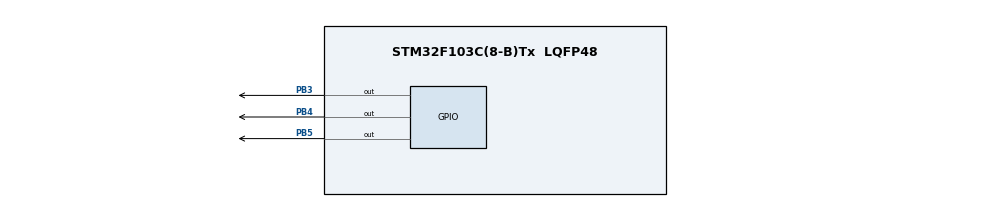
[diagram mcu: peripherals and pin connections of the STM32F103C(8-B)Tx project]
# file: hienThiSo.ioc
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Mcu.Family=STM32F1
Mcu.Name=STM32F103C(8-B)Tx
Mcu.Package=LQFP48
NVIC.PriorityGroup=NVIC_PRIORITYGROUP_4
PA13.Mode=Serial_Wire
PA13.Signal=SYS_JTMS-SWDIO
PA14.Mode=Serial_Wire
PA14.Signal=SYS_JTCK-SWCLK
PB3.Signal=GPIO_Output
PB4.Signal=GPIO_Output
PB5.Signal=GPIO_Output
ProjectManager.HeapSize=0x200
ProjectManager.StackSize=0x400
ProjectManager.TargetToolchain=MDK-ARM V5.32
RCC.APB1Freq_Value=8000000
RCC.APB2Freq_Value=8000000
board=custom

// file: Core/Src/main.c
/* USER CODE BEGIN Header */
/**
  ******************************************************************************
  * @file           : main.c
  * @brief          : Main program body
  ******************************************************************************
  * @attention
  *
  * Copyright (c) 2023 STMicroelectronics.
  * All rights reserved.
  *
  * This software is licensed under terms that can be found in the LICENSE file
  * in the root directory of this software component.
  * If no LICENSE file comes with this software, it is provided AS-IS.
  *
  ******************************************************************************
  */
/* USER CODE END Header */
#include "main.h"
#include "stdio.h"
#include <math.h>

/* USER CODE BEGIN PV */
int m[10]={0xc0,0xf9,0xa4,0xb0,0x99,0x92,0x82,0xf8,0x80,0x90};
int DATA1;
int SCK1;
int SCL1;
const uint8_t LEDTABLE[]={0B00000010,0B10011110,0B00100100,
												0B00001100,0B10011000,0B01001000,
												0B01000000,0B00011110,0B00000000,
												0B00001000};
/* USER CODE END PV */

void SystemClock_Config(void);
static void MX_GPIO_Init(void);

/* USER CODE BEGIN 0 */

	void HIEN_THI( uint8_t n)
	{
		for(int i = 0; i<8; i++){
			HAL_GPIO_WritePin(GPIOB, GPIO_PIN_5,(LEDTABLE[n]>>i)&1);
			HAL_GPIO_WritePin(GPIOB, GPIO_PIN_3, GPIO_PIN_SET);
			HAL_GPIO_WritePin(GPIOB, GPIO_PIN_3, GPIO_PIN_RESET);
		}
	}
	void HienChuoi(char x){
		int led[8];

		for (int i=0; i<8; i++){
				led[i] = fmod(x,(pow(10,i)));

					led[i] = atoi(x) ;

				HIEN_THI(led[i]);
		}
	}
/* USER CODE END 0 */

int main(void)
{

  /* MCU Configuration--------------------------------------------------------*/

  /* Reset of all peripherals, Initializes the Flash interface and the Systick. */
  HAL_Init();

  /* Configure the system clock */
  SystemClock_Config();

  /* Initialize all configured peripherals */
  MX_GPIO_Init();
  /* USER CODE BEGIN 2 */
	HAL_GPIO_WritePin(GPIOB, GPIO_PIN_3, GPIO_PIN_RESET);
	HAL_GPIO_WritePin(GPIOB, GPIO_PIN_4, GPIO_PIN_RESET);
	HAL_GPIO_WritePin(GPIOB, GPIO_PIN_5, GPIO_PIN_RESET);

	HienChuoi(3333333);
	/*
	HIEN_THI(4);
	HIEN_THI(6);
	HIEN_THI(4);
	HIEN_THI(1);
	HIEN_THI(0);
	HIEN_THI(2);
	*/

  HAL_GPIO_WritePin(GPIOB, GPIO_PIN_4, GPIO_PIN_SET); // SELECT

	HAL_Delay(1);

	HAL_GPIO_WritePin(GPIOB, GPIO_PIN_4, GPIO_PIN_RESET); // SELECT

	HAL_Delay(1);

		//HIEN_THI(mot);
		//HIEN_THI(hai);

  /* USER CODE END 2 */

  /* Infinite loop */
  while (1)
  {

}
}
void SystemClock_Config(void)
{
  RCC_OscInitTypeDef RCC_OscInitStruct = {0};
  RCC_ClkInitTypeDef RCC_ClkInitStruct = {0};

  /** Initializes the RCC Oscillators according to the specified parameters
  * in the RCC_OscInitTypeDef structure.
  */
  RCC_OscInitStruct.OscillatorType = RCC_OSCILLATORTYPE_HSI;
  RCC_OscInitStruct.HSIState = RCC_HSI_ON;
  RCC_OscInitStruct.HSICalibrationValue = RCC_HSICALIBRATION_DEFAULT;
  RCC_OscInitStruct.PLL.PLLState = RCC_PLL_NONE;
  if (HAL_RCC_OscConfig(&RCC_OscInitStruct) != HAL_OK)
  {
    Error_Handler();
  }

  /** Initializes the CPU, AHB and APB buses clocks
  */
  RCC_ClkInitStruct.ClockType = RCC_CLOCKTYPE_HCLK|RCC_CLOCKTYPE_SYSCLK
                              |RCC_CLOCKTYPE_PCLK1|RCC_CLOCKTYPE_PCLK2;
  RCC_ClkInitStruct.SYSCLKSource = RCC_SYSCLKSOURCE_HSI;
  RCC_ClkInitStruct.AHBCLKDivider = RCC_SYSCLK_DIV1;
  RCC_ClkInitStruct.APB1CLKDivider = RCC_HCLK_DIV1;
  RCC_ClkInitStruct.APB2CLKDivider = RCC_HCLK_DIV1;

  if (HAL_RCC_ClockConfig(&RCC_ClkInitStruct, FLASH_LATENCY_0) != HAL_OK)
  {
    Error_Handler();
  }
}

static void MX_GPIO_Init(void)
{
  GPIO_InitTypeDef GPIO_InitStruct = {0};

  /* GPIO Ports Clock Enable */
  __HAL_RCC_GPIOA_CLK_ENABLE();
  __HAL_RCC_GPIOB_CLK_ENABLE();

  /*Configure GPIO pin Output Level */
  HAL_GPIO_WritePin(GPIOB, GPIO_PIN_3|GPIO_PIN_4|GPIO_PIN_5, GPIO_PIN_RESET);

  /*Configure GPIO pins : PB3 PB4 PB5 */
  GPIO_InitStruct.Pin = GPIO_PIN_3|GPIO_PIN_4|GPIO_PIN_5;
  GPIO_InitStruct.Mode = GPIO_MODE_OUTPUT_PP;
  GPIO_InitStruct.Pull = GPIO_NOPULL;
  GPIO_InitStruct.Speed = GPIO_SPEED_FREQ_LOW;
  HAL_GPIO_Init(GPIOB, &GPIO_InitStruct);

}

void Error_Handler(void)
{
  __disable_irq();
  while (1)
  {
  }
}
